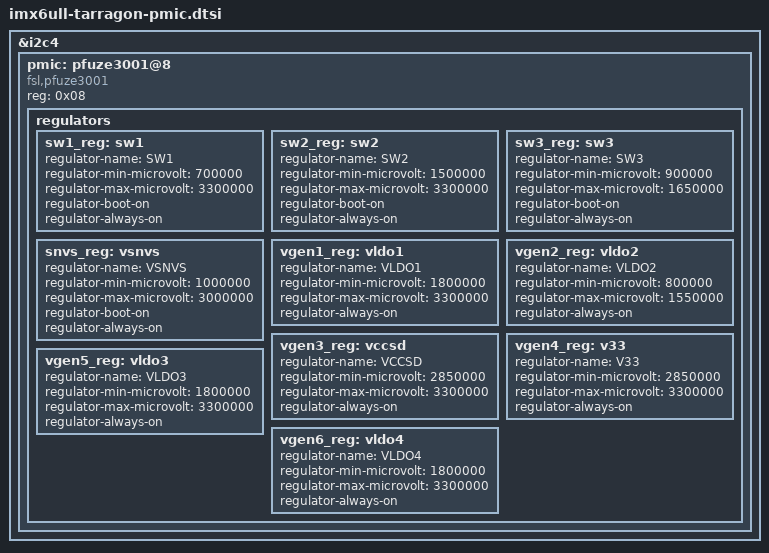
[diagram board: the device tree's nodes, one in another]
&i2c4 {
	pmic: pfuze3001@8 {
		compatible = "fsl,pfuze3001";
		reg = <0x08>;

		regulators {
			sw1_reg: sw1 {
				regulator-name = "SW1";
				regulator-min-microvolt = <700000>;
				regulator-max-microvolt = <3300000>;
				regulator-boot-on;
				regulator-always-on;
			};

			sw2_reg: sw2 {
				regulator-name = "SW2";
				regulator-min-microvolt = <1500000>;
				regulator-max-microvolt = <3300000>;
				regulator-boot-on;
				regulator-always-on;
			};

			sw3_reg: sw3 {
				regulator-name = "SW3";
				regulator-min-microvolt = <900000>;
				regulator-max-microvolt = <1650000>;
				regulator-boot-on;
				regulator-always-on;
			};

			snvs_reg: vsnvs {
				regulator-name = "VSNVS";
				regulator-min-microvolt = <1000000>;
				regulator-max-microvolt = <3000000>;
				regulator-boot-on;
				regulator-always-on;
			};

			vgen1_reg: vldo1 {
				regulator-name = "VLDO1";
				regulator-min-microvolt = <1800000>;
				regulator-max-microvolt = <3300000>;
				regulator-always-on;
			};

			vgen2_reg: vldo2 {
				regulator-name = "VLDO2";
				regulator-min-microvolt = <800000>;
				regulator-max-microvolt = <1550000>;
				regulator-always-on;
			};

			vgen3_reg: vccsd {
				regulator-name = "VCCSD";
				regulator-min-microvolt = <2850000>;
				regulator-max-microvolt = <3300000>;
				regulator-always-on;
			};

			vgen4_reg: v33 {
				regulator-name = "V33";
				regulator-min-microvolt = <2850000>;
				regulator-max-microvolt = <3300000>;
				regulator-always-on;
			};

			vgen5_reg: vldo3 {
				regulator-name = "VLDO3";
				regulator-min-microvolt = <1800000>;
				regulator-max-microvolt = <3300000>;
				regulator-always-on;
			};

			vgen6_reg: vldo4 {
				regulator-name = "VLDO4";
				regulator-min-microvolt = <1800000>;
				regulator-max-microvolt = <3300000>;
				regulator-always-on;
			};
		};
	};
};
